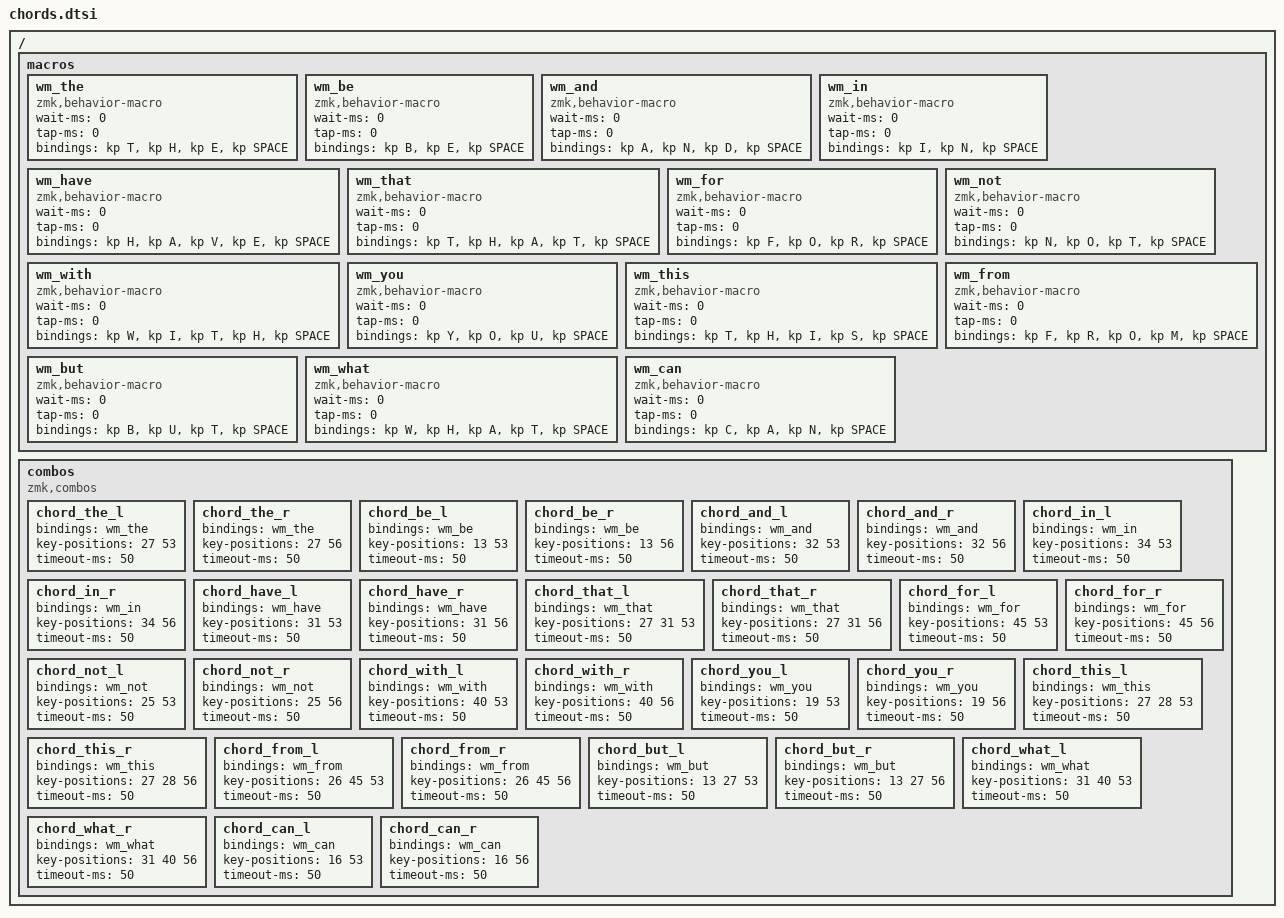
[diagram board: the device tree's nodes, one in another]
/* Auto-generated by scripts/gen-chords.py — do not edit by hand */

/ {
    macros {
        wm_the: wm_the {
            compatible = "zmk,behavior-macro";
            #binding-cells = <0>;
            wait-ms = <0>;
            tap-ms = <0>;
            bindings = <&kp T &kp H &kp E &kp SPACE>;
        };

        wm_be: wm_be {
            compatible = "zmk,behavior-macro";
            #binding-cells = <0>;
            wait-ms = <0>;
            tap-ms = <0>;
            bindings = <&kp B &kp E &kp SPACE>;
        };

        wm_and: wm_and {
            compatible = "zmk,behavior-macro";
            #binding-cells = <0>;
            wait-ms = <0>;
            tap-ms = <0>;
            bindings = <&kp A &kp N &kp D &kp SPACE>;
        };

        wm_in: wm_in {
            compatible = "zmk,behavior-macro";
            #binding-cells = <0>;
            wait-ms = <0>;
            tap-ms = <0>;
            bindings = <&kp I &kp N &kp SPACE>;
        };

        wm_have: wm_have {
            compatible = "zmk,behavior-macro";
            #binding-cells = <0>;
            wait-ms = <0>;
            tap-ms = <0>;
            bindings = <&kp H &kp A &kp V &kp E &kp SPACE>;
        };

        wm_that: wm_that {
            compatible = "zmk,behavior-macro";
            #binding-cells = <0>;
            wait-ms = <0>;
            tap-ms = <0>;
            bindings = <&kp T &kp H &kp A &kp T &kp SPACE>;
        };

        wm_for: wm_for {
            compatible = "zmk,behavior-macro";
            #binding-cells = <0>;
            wait-ms = <0>;
            tap-ms = <0>;
            bindings = <&kp F &kp O &kp R &kp SPACE>;
        };

        wm_not: wm_not {
            compatible = "zmk,behavior-macro";
            #binding-cells = <0>;
            wait-ms = <0>;
            tap-ms = <0>;
            bindings = <&kp N &kp O &kp T &kp SPACE>;
        };

        wm_with: wm_with {
            compatible = "zmk,behavior-macro";
            #binding-cells = <0>;
            wait-ms = <0>;
            tap-ms = <0>;
            bindings = <&kp W &kp I &kp T &kp H &kp SPACE>;
        };

        wm_you: wm_you {
            compatible = "zmk,behavior-macro";
            #binding-cells = <0>;
            wait-ms = <0>;
            tap-ms = <0>;
            bindings = <&kp Y &kp O &kp U &kp SPACE>;
        };

        wm_this: wm_this {
            compatible = "zmk,behavior-macro";
            #binding-cells = <0>;
            wait-ms = <0>;
            tap-ms = <0>;
            bindings = <&kp T &kp H &kp I &kp S &kp SPACE>;
        };

        wm_from: wm_from {
            compatible = "zmk,behavior-macro";
            #binding-cells = <0>;
            wait-ms = <0>;
            tap-ms = <0>;
            bindings = <&kp F &kp R &kp O &kp M &kp SPACE>;
        };

        wm_but: wm_but {
            compatible = "zmk,behavior-macro";
            #binding-cells = <0>;
            wait-ms = <0>;
            tap-ms = <0>;
            bindings = <&kp B &kp U &kp T &kp SPACE>;
        };

        wm_what: wm_what {
            compatible = "zmk,behavior-macro";
            #binding-cells = <0>;
            wait-ms = <0>;
            tap-ms = <0>;
            bindings = <&kp W &kp H &kp A &kp T &kp SPACE>;
        };

        wm_can: wm_can {
            compatible = "zmk,behavior-macro";
            #binding-cells = <0>;
            wait-ms = <0>;
            tap-ms = <0>;
            bindings = <&kp C &kp A &kp N &kp SPACE>;
        };
    };

    combos {
        compatible = "zmk,combos";

        chord_the_l {
            bindings = <&wm_the>;
            key-positions = <27 53>;
            timeout-ms = <50>;
        };

        chord_the_r {
            bindings = <&wm_the>;
            key-positions = <27 56>;
            timeout-ms = <50>;
        };

        chord_be_l {
            bindings = <&wm_be>;
            key-positions = <13 53>;
            timeout-ms = <50>;
        };

        chord_be_r {
            bindings = <&wm_be>;
            key-positions = <13 56>;
            timeout-ms = <50>;
        };

        chord_and_l {
            bindings = <&wm_and>;
            key-positions = <32 53>;
            timeout-ms = <50>;
        };

        chord_and_r {
            bindings = <&wm_and>;
            key-positions = <32 56>;
            timeout-ms = <50>;
        };

        chord_in_l {
            bindings = <&wm_in>;
            key-positions = <34 53>;
            timeout-ms = <50>;
        };

        chord_in_r {
            bindings = <&wm_in>;
            key-positions = <34 56>;
            timeout-ms = <50>;
        };

        chord_have_l {
            bindings = <&wm_have>;
            key-positions = <31 53>;
            timeout-ms = <50>;
        };

        chord_have_r {
            bindings = <&wm_have>;
            key-positions = <31 56>;
            timeout-ms = <50>;
        };

        chord_that_l {
            bindings = <&wm_that>;
            key-positions = <27 31 53>;
            timeout-ms = <50>;
        };

        chord_that_r {
            bindings = <&wm_that>;
            key-positions = <27 31 56>;
            timeout-ms = <50>;
        };

        chord_for_l {
            bindings = <&wm_for>;
            key-positions = <45 53>;
            timeout-ms = <50>;
        };

        chord_for_r {
            bindings = <&wm_for>;
            key-positions = <45 56>;
            timeout-ms = <50>;
        };

        chord_not_l {
            bindings = <&wm_not>;
            key-positions = <25 53>;
            timeout-ms = <50>;
        };

        chord_not_r {
            bindings = <&wm_not>;
            key-positions = <25 56>;
            timeout-ms = <50>;
        };

        chord_with_l {
            bindings = <&wm_with>;
            key-positions = <40 53>;
            timeout-ms = <50>;
        };

        chord_with_r {
            bindings = <&wm_with>;
            key-positions = <40 56>;
            timeout-ms = <50>;
        };

        chord_you_l {
            bindings = <&wm_you>;
            key-positions = <19 53>;
            timeout-ms = <50>;
        };

        chord_you_r {
            bindings = <&wm_you>;
            key-positions = <19 56>;
            timeout-ms = <50>;
        };

        chord_this_l {
            bindings = <&wm_this>;
            key-positions = <27 28 53>;
            timeout-ms = <50>;
        };

        chord_this_r {
            bindings = <&wm_this>;
            key-positions = <27 28 56>;
            timeout-ms = <50>;
        };

        chord_from_l {
            bindings = <&wm_from>;
            key-positions = <26 45 53>;
            timeout-ms = <50>;
        };

        chord_from_r {
            bindings = <&wm_from>;
            key-positions = <26 45 56>;
            timeout-ms = <50>;
        };

        chord_but_l {
            bindings = <&wm_but>;
            key-positions = <13 27 53>;
            timeout-ms = <50>;
        };

        chord_but_r {
            bindings = <&wm_but>;
            key-positions = <13 27 56>;
            timeout-ms = <50>;
        };

        chord_what_l {
            bindings = <&wm_what>;
            key-positions = <31 40 53>;
            timeout-ms = <50>;
        };

        chord_what_r {
            bindings = <&wm_what>;
            key-positions = <31 40 56>;
            timeout-ms = <50>;
        };

        chord_can_l {
            bindings = <&wm_can>;
            key-positions = <16 53>;
            timeout-ms = <50>;
        };

        chord_can_r {
            bindings = <&wm_can>;
            key-positions = <16 56>;
            timeout-ms = <50>;
        };
    };
};
